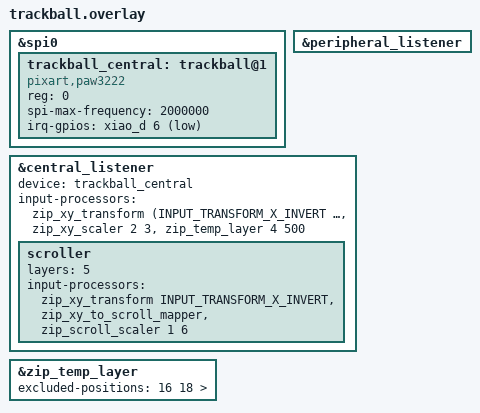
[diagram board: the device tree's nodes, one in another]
&spi0 {
    status = "okay";
    trackball_central: trackball@1 {
        status = "okay";
        compatible = "pixart,paw3222";
        reg = <0>;
        spi-max-frequency = <2000000>;
        irq-gpios = <&xiao_d 6 (GPIO_ACTIVE_LOW | GPIO_PULL_UP)>;
    };
};

&peripheral_listener {
    status = "okay";
};

&central_listener {
    status = "okay";
    device = <&trackball_central>;
    
    input-processors = 
        <&zip_xy_transform (INPUT_TRANSFORM_X_INVERT | INPUT_TRANSFORM_Y_INVERT)>,
        <&zip_xy_scaler 2 3>,
        <&zip_temp_layer 4 500>;
    
    scroller {
        layers = <5>;
        input-processors = 
            <&zip_xy_transform INPUT_TRANSFORM_X_INVERT>,  // 順序を変更：マッパーの前に配置
            <&zip_xy_to_scroll_mapper>,
            <&zip_scroll_scaler 1 6>;
    };
};

// MB1(位置16)とMB2(位置18)以外のキーを押すとレイヤー4から即座に抜ける
&zip_temp_layer {
    excluded-positions = 
        16  // MB1（左クリック）
        18  // MB2（右クリック）
    >;
};
